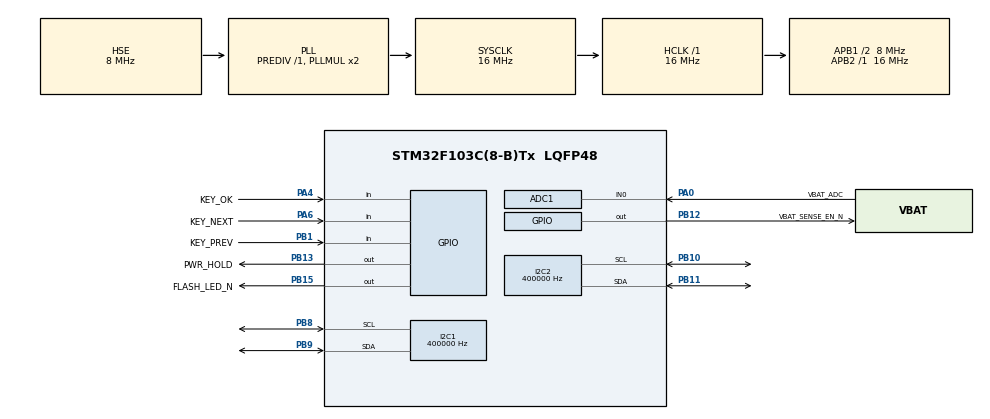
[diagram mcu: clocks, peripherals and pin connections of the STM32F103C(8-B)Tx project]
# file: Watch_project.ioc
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ADC1.Channel-0\#ChannelRegularConversion=ADC_CHANNEL_0
ADC1.NbrOfConversionFlag=1
ADC1.Rank-0\#ChannelRegularConversion=1
ADC1.SamplingTime-0\#ChannelRegularConversion=ADC_SAMPLETIME_55CYCLES_5
ADC1.master=1
I2C1.ClockSpeed=400000
I2C2.ClockSpeed=400000
Mcu.Family=STM32F1
Mcu.Name=STM32F103C(8-B)Tx
Mcu.Package=LQFP48
NVIC.PriorityGroup=NVIC_PRIORITYGROUP_4
PA0-WKUP.GPIO_Label=VBAT_ADC
PA0-WKUP.Signal=ADCx_IN0
PA13.Mode=Serial_Wire
PA13.Signal=SYS_JTMS-SWDIO
PA14.Mode=Serial_Wire
PA14.Signal=SYS_JTCK-SWCLK
PA4.GPIO_Label=KEY_OK
PA4.GPIO_PuPd=GPIO_PULLUP
PA4.Signal=GPIO_Input
PA6.GPIO_Label=KEY_NEXT
PA6.GPIO_PuPd=GPIO_PULLUP
PA6.Signal=GPIO_Input
PB1.GPIO_Label=KEY_PREV
PB1.GPIO_PuPd=GPIO_PULLUP
PB1.Signal=GPIO_Input
PB10.Mode=I2C
PB10.Signal=I2C2_SCL
PB11.Mode=I2C
PB11.Signal=I2C2_SDA
PB12.GPIO_Label=VBAT_SENSE_EN_N
PB12.Signal=GPIO_Output
PB13.GPIO_Label=PWR_HOLD
PB13.PinState=GPIO_PIN_SET
PB13.Signal=GPIO_Output
PB15.GPIO_Label=FLASH_LED_N
PB15.PinState=GPIO_PIN_SET
PB15.Signal=GPIO_Output
PB8.Mode=I2C
PB8.Signal=I2C1_SCL
PB9.Mode=I2C
PB9.Signal=I2C1_SDA
PC14-OSC32_IN.Mode=LSE-External-Oscillator
PC14-OSC32_IN.Signal=RCC_OSC32_IN
PC15-OSC32_OUT.Mode=LSE-External-Oscillator
PC15-OSC32_OUT.Signal=RCC_OSC32_OUT
PD0-OSC_IN.Mode=HSE-External-Oscillator
PD0-OSC_IN.Signal=RCC_OSC_IN
PD1-OSC_OUT.Mode=HSE-External-Oscillator
PD1-OSC_OUT.Signal=RCC_OSC_OUT
ProjectManager.HeapSize=0x200
ProjectManager.StackSize=0x400
ProjectManager.TargetToolchain=CMake
RCC.AHBFreq_Value=16000000
RCC.APB1CLKDivider=RCC_HCLK_DIV2
RCC.APB1Freq_Value=8000000
RCC.APB1TimFreq_Value=16000000
RCC.APB2Freq_Value=16000000
RCC.APB2TimFreq_Value=16000000
RCC.HCLKFreq_Value=16000000
RCC.PLLSourceVirtual=RCC_PLLSOURCE_HSE
RCC.RTCClockSelection=RCC_RTCCLKSOURCE_LSE
RCC.SYSCLKFreq_VALUE=16000000
RCC.SYSCLKSource=RCC_SYSCLKSOURCE_PLLCLK
RCC.USBFreq_Value=16000000
SH.ADCx_IN0.0=ADC1_IN0,IN0
VP_RTC_No_RTC_Output.Mode=RTC_OUT_NO
VP_RTC_VS_RTC_Activate.Mode=RTC_Enabled
VP_RTC_VS_RTC_Calendar.Mode=RTC_Calendar
board=custom

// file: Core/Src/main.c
/* USER CODE BEGIN Header */
/**
  ******************************************************************************
  * @file           : main.c
  * @brief          : Main program body
  ******************************************************************************
  * @attention
  *
  * Copyright (c) 2026 STMicroelectronics.
  * All rights reserved.
  *
  * This software is licensed under terms that can be found in the LICENSE file
  * in the root directory of this software component.
  * If no LICENSE file comes with this software, it is provided AS-IS.
  *
  ******************************************************************************
  */
/* USER CODE END Header */
#include "main.h"
#include "adc.h"
#include "i2c.h"
#include "rtc.h"
#include "gpio.h"

/* USER CODE BEGIN Includes */
#include "board.h"
#include "watch_app.h"

/* USER CODE END Includes */

void SystemClock_Config(void);

int main(void)
{

  /* MCU Configuration--------------------------------------------------------*/

  /* Reset of all peripherals, Initializes the Flash interface and the Systick. */
  HAL_Init();

  /* USER CODE BEGIN Init */
  board_power_hold_early();

  /* USER CODE END Init */

  /* Configure the system clock */
  SystemClock_Config();

  /* Initialize all configured peripherals */
  MX_GPIO_Init();
  MX_ADC1_Init();
  MX_I2C1_Init();
  MX_I2C2_Init();
  MX_RTC_Init();
  /* USER CODE BEGIN 2 */
  board_init();
  watch_app_init();

  /* USER CODE END 2 */

  /* Infinite loop */
  while (1)
  {

    /* USER CODE BEGIN 3 */
    watch_app_process();
    __WFI();
  }
  /* USER CODE END 3 */
}

void SystemClock_Config(void)
{
  RCC_OscInitTypeDef RCC_OscInitStruct = {0};
  RCC_ClkInitTypeDef RCC_ClkInitStruct = {0};
  RCC_PeriphCLKInitTypeDef PeriphClkInit = {0};

  /** Initializes the RCC Oscillators according to the specified parameters
  * in the RCC_OscInitTypeDef structure.
  */
  RCC_OscInitStruct.OscillatorType = RCC_OSCILLATORTYPE_HSE|RCC_OSCILLATORTYPE_LSE;
  RCC_OscInitStruct.HSEState = RCC_HSE_ON;
  RCC_OscInitStruct.HSEPredivValue = RCC_HSE_PREDIV_DIV1;
  RCC_OscInitStruct.LSEState = RCC_LSE_ON;
  RCC_OscInitStruct.HSIState = RCC_HSI_ON;
  RCC_OscInitStruct.PLL.PLLState = RCC_PLL_ON;
  RCC_OscInitStruct.PLL.PLLSource = RCC_PLLSOURCE_HSE;
  RCC_OscInitStruct.PLL.PLLMUL = RCC_PLL_MUL2;
  if (HAL_RCC_OscConfig(&RCC_OscInitStruct) != HAL_OK)
  {
    Error_Handler();
  }

  /** Initializes the CPU, AHB and APB buses clocks
  */
  RCC_ClkInitStruct.ClockType = RCC_CLOCKTYPE_HCLK|RCC_CLOCKTYPE_SYSCLK
                              |RCC_CLOCKTYPE_PCLK1|RCC_CLOCKTYPE_PCLK2;
  RCC_ClkInitStruct.SYSCLKSource = RCC_SYSCLKSOURCE_PLLCLK;
  RCC_ClkInitStruct.AHBCLKDivider = RCC_SYSCLK_DIV1;
  RCC_ClkInitStruct.APB1CLKDivider = RCC_HCLK_DIV2;
  RCC_ClkInitStruct.APB2CLKDivider = RCC_HCLK_DIV1;

  if (HAL_RCC_ClockConfig(&RCC_ClkInitStruct, FLASH_LATENCY_0) != HAL_OK)
  {
    Error_Handler();
  }
  PeriphClkInit.PeriphClockSelection = RCC_PERIPHCLK_RTC|RCC_PERIPHCLK_ADC;
  PeriphClkInit.RTCClockSelection = RCC_RTCCLKSOURCE_LSE;
  PeriphClkInit.AdcClockSelection = RCC_ADCPCLK2_DIV2;
  if (HAL_RCCEx_PeriphCLKConfig(&PeriphClkInit) != HAL_OK)
  {
    Error_Handler();
  }
}

void Error_Handler(void)
{
  __disable_irq();
  while (1)
  {
  }
}
